# STM32WL5x_CM0P register map
File version: 1.5
CPU: CM0 r0p1, little endian, MPU, no FPU, 4 interrupt priority bits
Registers are 32-bit, read-write, reset 0x0 unless marked. A register's access mark holds for its fields unless they carry their own. Offsets are from the block's base; [hi:lo] are bit positions; {n}, {i} and the like mark numbered series.

## GPIOA — General-purpose I/Os
Base 0x48000000
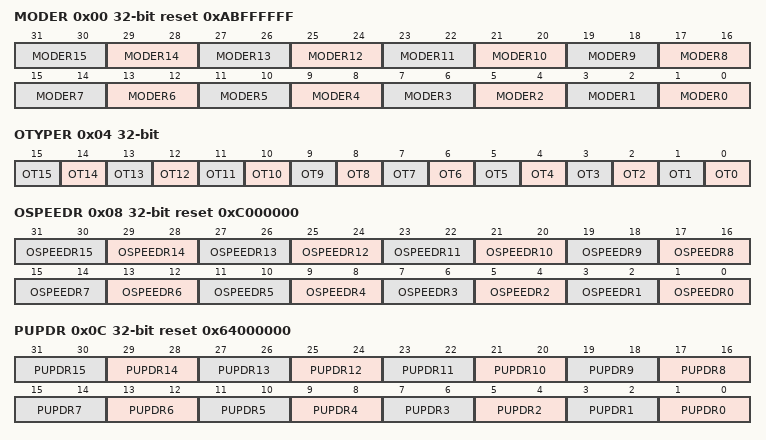
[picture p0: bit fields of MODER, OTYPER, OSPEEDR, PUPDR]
0x00 MODER reset 0xABFFFFFF — GPIO port mode register
  [2n+1:2n] MODER{n} (n=0..15)
0x04 OTYPER — GPIO port output type register
  [n] OT{n} (n=0..15) — Port x configuration bits (y = 0..15)
0x08 OSPEEDR reset 0xC000000 — GPIO port output speed register
  [2n+1:2n] OSPEEDR{n} (n=0..15) — Port x configuration bits (y = 0..15)
0x0C PUPDR reset 0x64000000 — GPIO port pull-up/pull-down register
  [2n+1:2n] PUPDR{n} (n=0..15) — Port x configuration bits (y = 0..15)
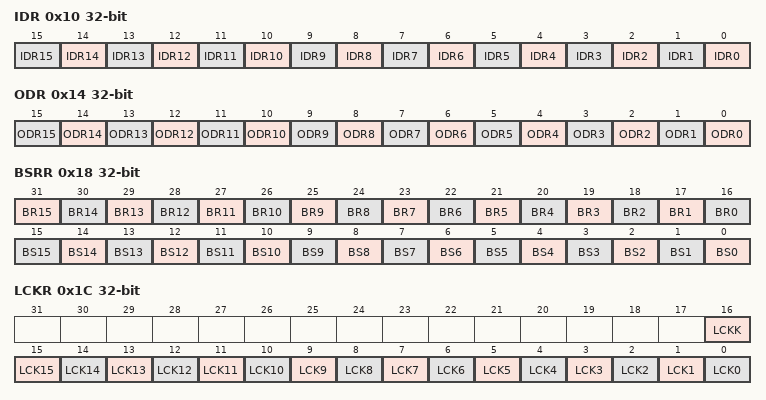
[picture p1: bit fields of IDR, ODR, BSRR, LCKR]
0x10 IDR ro — GPIO port input data register
  [n] IDR{n} (n=0..15) — Port input data (y = 0..15)
0x14 ODR — GPIO port output data register
  [n] ODR{n} (n=0..15) — Port output data (y = 0..15)
0x18 BSRR wo — GPIO port bit set/reset register
  [n+16] BR{n} (n=1..15) — Port x reset bit y (y = 0..15)
  [16] BR0 — Port x set bit y (y= 0..15)
  [n] BS{n} (n=0..15) — Port x set bit y (y= 0..15)
0x1C LCKR — GPIO port configuration lock register
  [16] LCKK — Port x lock bit y (y= 0..15)
  [n] LCK{n} (n=0..15) — Port x lock bit y (y= 0..15)
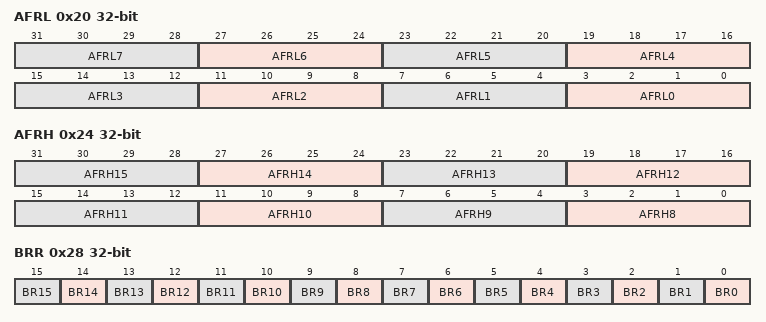
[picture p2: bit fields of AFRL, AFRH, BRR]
0x20 AFRL — GPIO alternate function low register
  [4n+3:4n] AFRL{n} (n=0..7) — Alternate function selection for port x bit y (y = 0..7)
0x24 AFRH — GPIO alternate function high register
  [4n-29:4n-32] AFRH{n} (n=8..15) — Alternate function selection for port x bit y (y = 8..15)
0x28 BRR — GPIO port bit reset register
  [n] BR{n} (n=0..15) — Port Reset bit

## GPIOB — General-purpose I/Os
Base 0x48000400
Registers as GPIOA; these are added or differ:
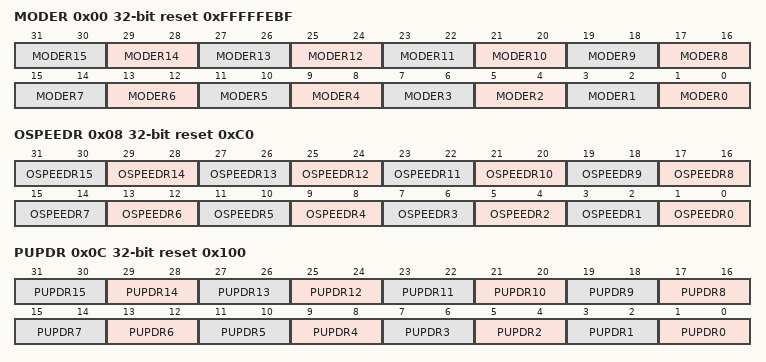
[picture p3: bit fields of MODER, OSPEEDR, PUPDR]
0x00 MODER reset 0xFFFFFEBF — GPIO port mode register
  [2n+1:2n] MODER{n} (n=0..15) — Port x configuration bits (y = 0..15)
0x08 OSPEEDR reset 0xC0 — GPIO port output speed register
  [2n+1:2n] OSPEEDR{n} (n=0..15) — Port x configuration bits (y = 0..15)
0x0C PUPDR reset 0x100 — GPIO port pull-up/pull-down register
  [2n+1:2n] PUPDR{n} (n=0..15) — Port x configuration bits (y = 0..15)

## GPIOC — General-purpose I/Os
Base 0x48000800
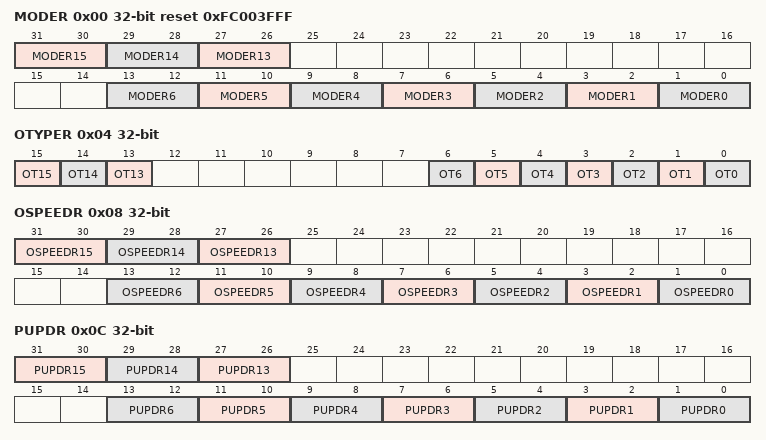
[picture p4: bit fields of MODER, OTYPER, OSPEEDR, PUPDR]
0x00 MODER reset 0xFC003FFF — GPIO port mode register
  [31:30] MODER15 — Port x configuration bits (y = 0..15)
  [29:28] MODER14 — Port x configuration bits (y = 0..15)
  [27:26] MODER13 — Port x configuration bits (y = 0..15)
  [2n+1:2n] MODER{n} (n=0..6) — Port x configuration bits (y = 0..15)
0x04 OTYPER — GPIO port output type register
  [15] OT15 — Port x configuration bits (y = 0..15)
  [14] OT14 — Port x configuration bits (y = 0..15)
  [13] OT13 — Port x configuration bits (y = 0..15)
  [n] OT{n} (n=0..6) — Port x configuration bits (y = 0..15)
0x08 OSPEEDR — GPIO port output speed register
  [31:30] OSPEEDR15 — Port x configuration bits (y = 0..15)
  [29:28] OSPEEDR14 — Port x configuration bits (y = 0..15)
  [27:26] OSPEEDR13 — Port x configuration bits (y = 0..15)
  [2n+1:2n] OSPEEDR{n} (n=0..6) — Port x configuration bits (y = 0..15)
0x0C PUPDR — GPIO port pull-up/pull-down register
  [31:30] PUPDR15 — Port x configuration bits (y = 0..15)
  [29:28] PUPDR14 — Port x configuration bits (y = 0..15)
  [27:26] PUPDR13 — Port x configuration bits (y = 0..15)
  [2n+1:2n] PUPDR{n} (n=0..6) — Port x configuration bits (y = 0..15)
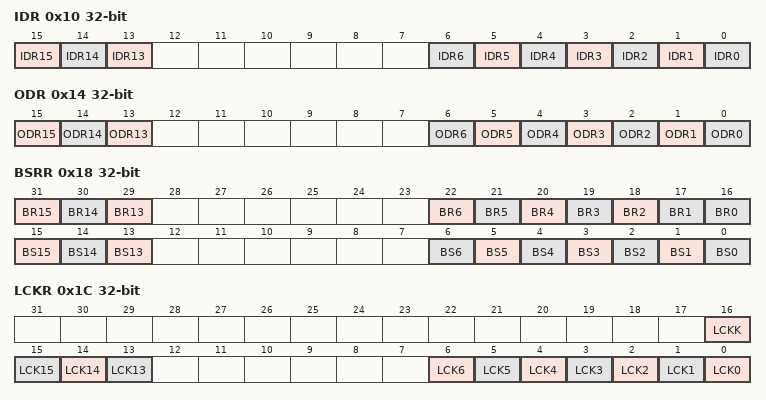
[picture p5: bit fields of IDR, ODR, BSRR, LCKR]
0x10 IDR ro — GPIO port input data register
  [15] IDR15 — Port input data (y = 0..15)
  [14] IDR14 — Port input data (y = 0..15)
  [13] IDR13 — Port input data (y = 0..15)
  [n] IDR{n} (n=0..6) — Port input data (y = 0..15)
0x14 ODR — GPIO port output data register
  [15] ODR15 — Port output data (y = 0..15)
  [14] ODR14 — Port output data (y = 0..15)
  [13] ODR13 — Port output data (y = 0..15)
  [n] ODR{n} (n=0..6) — Port output data (y = 0..15)
0x18 BSRR wo — GPIO port bit set/reset register
  [31] BR15 — Port x reset bit y (y = 0..15)
  [30] BR14 — Port x reset bit y (y = 0..15)
  [29] BR13 — Port x reset bit y (y = 0..15)
  [n+16] BR{n} (n=1..6) — Port x reset bit y (y = 0..15)
  [16] BR0 — Port x set bit y (y= 0..15)
  [15] BS15 — Port x set bit y (y= 0..15)
  [14] BS14 — Port x set bit y (y= 0..15)
  [13] BS13 — Port x set bit y (y= 0..15)
  [n] BS{n} (n=0..6) — Port x set bit y (y= 0..15)
0x1C LCKR — GPIO port configuration lock register
  [16] LCKK — Port x lock bit y (y= 0..15)
  [15] LCK15 — Port x lock bit y (y= 0..15)
  [14] LCK14 — Port x lock bit y (y= 0..15)
  [13] LCK13 — Port x lock bit y (y= 0..15)
  [n] LCK{n} (n=0..6) — Port x lock bit y (y= 0..15)
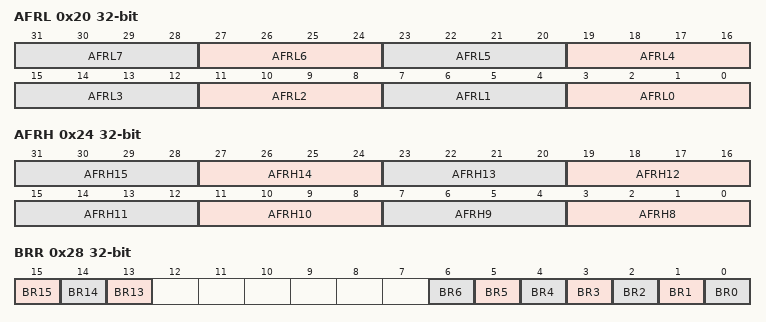
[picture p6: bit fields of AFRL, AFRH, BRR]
0x20 AFRL — GPIO alternate function low register
  [4n+3:4n] AFRL{n} (n=0..7) — Alternate function selection for port x bit y (y = 0..7)
0x24 AFRH — GPIO alternate function high register
  [4n-29:4n-32] AFRH{n} (n=8..15) — Alternate function selection for port x bit y (y = 8..15)
0x28 BRR — GPIO port bit reset register
  [15] BR15 — Port Reset bit
  [14] BR14 — Port Reset bit
  [13] BR13 — Port Reset bit
  [n] BR{n} (n=0..6) — Port Reset bit
